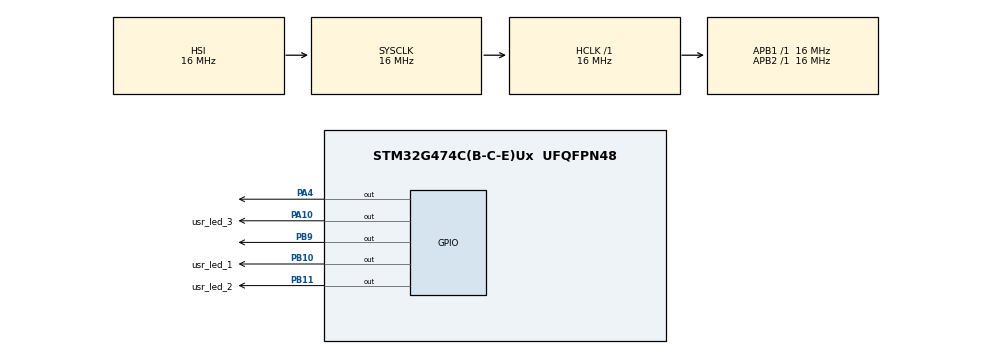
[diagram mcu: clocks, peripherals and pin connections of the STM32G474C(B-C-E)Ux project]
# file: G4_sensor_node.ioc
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Mcu.Family=STM32G4
Mcu.Name=STM32G474C(B-C-E)Ux
Mcu.Package=UFQFPN48
NVIC.PriorityGroup=NVIC_PRIORITYGROUP_4
PA10.GPIO_Label=usr_led_3
PA10.GPIO_PuPd=GPIO_PULLDOWN
PA10.PinState=GPIO_PIN_SET
PA10.Signal=GPIO_Output
PA13.Mode=Trace_Asynchronous_SW
PA13.Signal=SYS_JTMS-SWDIO
PA14.Mode=Trace_Asynchronous_SW
PA14.Signal=SYS_JTCK-SWCLK
PA4.PinState=GPIO_PIN_SET
PA4.Signal=GPIO_Output
PB10.GPIO_Label=usr_led_1
PB10.GPIO_PuPd=GPIO_PULLDOWN
PB10.PinState=GPIO_PIN_SET
PB10.Signal=GPIO_Output
PB11.GPIO_Label=usr_led_2
PB11.GPIO_PuPd=GPIO_PULLDOWN
PB11.PinState=GPIO_PIN_SET
PB11.Signal=GPIO_Output
PB3.Mode=Trace_Asynchronous_SW
PB3.Signal=SYS_JTDO-SWO
PB9.GPIO_PuPd=GPIO_PULLDOWN
PB9.PinState=GPIO_PIN_SET
PB9.Signal=GPIO_Output
ProjectManager.HeapSize=0x200
ProjectManager.StackSize=0x400
ProjectManager.TargetToolchain=CMake
RCC.ADC12Freq_Value=16000000
RCC.ADC345Freq_Value=16000000
RCC.AHBFreq_Value=16000000
RCC.APB1Freq_Value=16000000
RCC.APB1TimFreq_Value=16000000
RCC.APB2Freq_Value=16000000
RCC.APB2TimFreq_Value=16000000
RCC.CortexFreq_Value=16000000
RCC.EXTERNAL_CLOCK_VALUE=12288000
RCC.HCLKFreq_Value=16000000
RCC.HSE_VALUE=48000000
RCC.HSI48_VALUE=48000000
RCC.HSI_VALUE=16000000
RCC.SYSCLKFreq_VALUE=16000000
RCC.USBFreq_Value=64000000
RCC.VCOOutputFreq_Value=128000000
VP_SYS_VS_DBSignals.Mode=DisableDeadBatterySignals
board=custom

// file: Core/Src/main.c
/* USER CODE BEGIN Header */
/**
  ******************************************************************************
  * @file           : main.c
  * @brief          : Main program body
  ******************************************************************************
  * @attention
  *
  * Copyright (c) 2025 STMicroelectronics.
  * All rights reserved.
  *
  * This software is licensed under terms that can be found in the LICENSE file
  * in the root directory of this software component.
  * If no LICENSE file comes with this software, it is provided AS-IS.
  *
  ******************************************************************************
  */
/* USER CODE END Header */
#include "main.h"
#include "gpio.h"

void SystemClock_Config(void);

int main(void)
{

  /* MCU Configuration--------------------------------------------------------*/

  /* Reset of all peripherals, Initializes the Flash interface and the Systick. */
  HAL_Init();

  /* Configure the system clock */
  SystemClock_Config();

  /* Initialize all configured peripherals */
  MX_GPIO_Init();

  /* Infinite loop */
  /* USER CODE BEGIN WHILE */
  while (1)
  {
    // HAL_GPIO_TogglePin(GPIOB, GPIO_PIN_9);

    // HAL_GPIO_TogglePin(GPIOB, GPIO_PIN_10);

    HAL_GPIO_TogglePin(GPIOB, GPIO_PIN_11);

    // HAL_GPIO_TogglePin(GPIOA, GPIO_PIN_4);
    HAL_Delay(300);

    /* USER CODE END WHILE */

  }
}

void SystemClock_Config(void)
{
  RCC_OscInitTypeDef RCC_OscInitStruct = {0};
  RCC_ClkInitTypeDef RCC_ClkInitStruct = {0};

  /** Configure the main internal regulator output voltage
  */
  HAL_PWREx_ControlVoltageScaling(PWR_REGULATOR_VOLTAGE_SCALE1);

  /** Initializes the RCC Oscillators according to the specified parameters
  * in the RCC_OscInitTypeDef structure.
  */
  RCC_OscInitStruct.OscillatorType = RCC_OSCILLATORTYPE_HSI;
  RCC_OscInitStruct.HSIState = RCC_HSI_ON;
  RCC_OscInitStruct.HSICalibrationValue = RCC_HSICALIBRATION_DEFAULT;
  RCC_OscInitStruct.PLL.PLLState = RCC_PLL_NONE;
  if (HAL_RCC_OscConfig(&RCC_OscInitStruct) != HAL_OK)
  {
    Error_Handler();
  }

  /** Initializes the CPU, AHB and APB buses clocks
  */
  RCC_ClkInitStruct.ClockType = RCC_CLOCKTYPE_HCLK|RCC_CLOCKTYPE_SYSCLK
                              |RCC_CLOCKTYPE_PCLK1|RCC_CLOCKTYPE_PCLK2;
  RCC_ClkInitStruct.SYSCLKSource = RCC_SYSCLKSOURCE_HSI;
  RCC_ClkInitStruct.AHBCLKDivider = RCC_SYSCLK_DIV1;
  RCC_ClkInitStruct.APB1CLKDivider = RCC_HCLK_DIV1;
  RCC_ClkInitStruct.APB2CLKDivider = RCC_HCLK_DIV1;

  if (HAL_RCC_ClockConfig(&RCC_ClkInitStruct, FLASH_LATENCY_0) != HAL_OK)
  {
    Error_Handler();
  }
}

void Error_Handler(void)
{
  __disable_irq();
  while (1)
  {
  }
}
